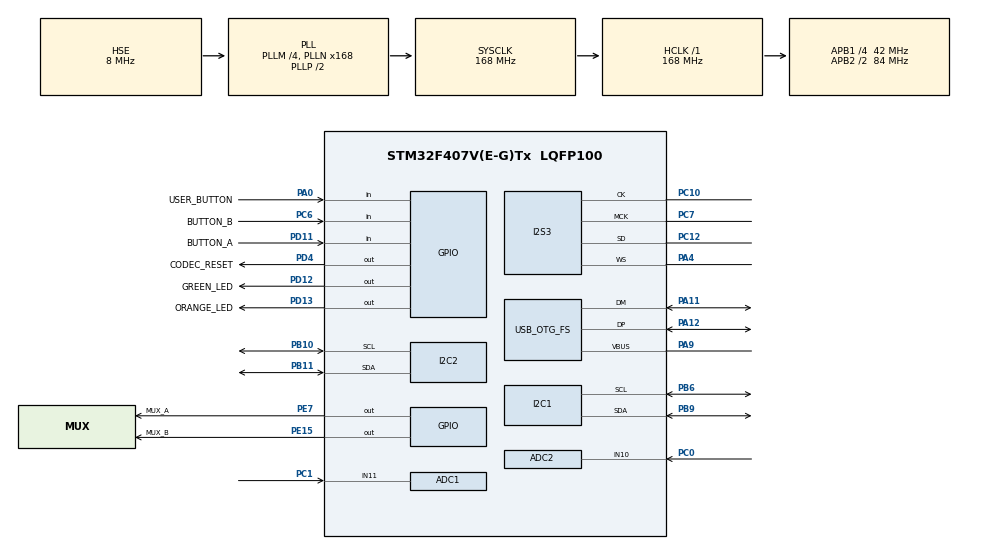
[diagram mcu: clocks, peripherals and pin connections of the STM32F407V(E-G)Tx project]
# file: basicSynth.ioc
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ADC1.Channel-1\#ChannelRegularConversion=ADC_CHANNEL_11
ADC1.ClockPrescaler=ADC_CLOCK_SYNC_PCLK_DIV8
ADC1.NbrOfConversionFlag=1
ADC1.Rank-1\#ChannelRegularConversion=1
ADC1.SamplingTime-1\#ChannelRegularConversion=ADC_SAMPLETIME_144CYCLES
ADC1.master=1
ADC2.Channel-0\#ChannelRegularConversion=ADC_CHANNEL_10
ADC2.ClockPrescaler=ADC_CLOCK_SYNC_PCLK_DIV8
ADC2.NbrOfConversionFlag=1
ADC2.Rank-0\#ChannelRegularConversion=1
ADC2.SamplingTime-0\#ChannelRegularConversion=ADC_SAMPLETIME_144CYCLES
Dma.I2C2_TX.1.Direction=DMA_MEMORY_TO_PERIPH
Dma.I2C2_TX.1.FIFOMode=DMA_FIFOMODE_DISABLE
Dma.I2C2_TX.1.Instance=DMA1_Stream7
Dma.I2C2_TX.1.MemDataAlignment=DMA_MDATAALIGN_BYTE
Dma.I2C2_TX.1.MemInc=DMA_MINC_ENABLE
Dma.I2C2_TX.1.Mode=DMA_NORMAL
Dma.I2C2_TX.1.PeriphDataAlignment=DMA_PDATAALIGN_BYTE
Dma.I2C2_TX.1.PeriphInc=DMA_PINC_DISABLE
Dma.I2C2_TX.1.Priority=DMA_PRIORITY_LOW
Dma.Request0=SPI3_TX
Dma.Request1=I2C2_TX
Dma.SPI3_TX.0.Direction=DMA_MEMORY_TO_PERIPH
Dma.SPI3_TX.0.FIFOMode=DMA_FIFOMODE_DISABLE
Dma.SPI3_TX.0.Instance=DMA1_Stream5
Dma.SPI3_TX.0.MemDataAlignment=DMA_MDATAALIGN_HALFWORD
Dma.SPI3_TX.0.MemInc=DMA_MINC_ENABLE
Dma.SPI3_TX.0.Mode=DMA_CIRCULAR
Dma.SPI3_TX.0.PeriphDataAlignment=DMA_PDATAALIGN_HALFWORD
Dma.SPI3_TX.0.PeriphInc=DMA_PINC_DISABLE
Dma.SPI3_TX.0.Priority=DMA_PRIORITY_VERY_HIGH
I2C2.I2C_Mode=I2C_Fast
I2S3.AudioFreq=I2S_AUDIOFREQ_48K
I2S3.ErrorAudioFreq=0.09 %
I2S3.FullDuplexMode=I2S_FULLDUPLEXMODE_DISABLE
I2S3.Instance=SPI$Index
I2S3.RealAudioFreq=48.046 KHz
I2S3.VirtualMode=I2S_MODE_MASTER
Mcu.Family=STM32F4
Mcu.Name=STM32F407V(E-G)Tx
Mcu.Package=LQFP100
NVIC.ADC_IRQn=true\:0\:0\:false\:false\:true\:true\:true\:true
NVIC.DMA1_Stream5_IRQn=true\:0\:0\:false\:false\:true\:false\:true\:true
NVIC.DMA1_Stream7_IRQn=true\:0\:0\:false\:false\:true\:false\:true\:true
NVIC.I2C2_ER_IRQn=true\:0\:0\:false\:false\:true\:true\:true\:true
NVIC.I2C2_EV_IRQn=true\:0\:0\:false\:false\:true\:true\:true\:true
NVIC.OTG_FS_IRQn=true\:0\:0\:false\:false\:true\:false\:true\:true
NVIC.PriorityGroup=NVIC_PRIORITYGROUP_4
NVIC.TIM4_IRQn=true\:0\:0\:false\:false\:true\:true\:true\:true
PA0-WKUP.GPIO_Label=USER_BUTTON
PA0-WKUP.GPIO_PuPd=GPIO_PULLDOWN
PA0-WKUP.Signal=GPIO_Input
PA11.Mode=Device_Only
PA11.Signal=USB_OTG_FS_DM
PA12.Mode=Device_Only
PA12.Signal=USB_OTG_FS_DP
PA4.Mode=Half_Duplex_Master
PA4.Signal=I2S3_WS
PA9.Mode=Activate_VBUS
PA9.Signal=USB_OTG_FS_VBUS
PB10.Mode=I2C
PB10.Signal=I2C2_SCL
PB11.Mode=I2C
PB11.Signal=I2C2_SDA
PB6.Mode=I2C
PB6.Signal=I2C1_SCL
PB9.Mode=I2C
PB9.Signal=I2C1_SDA
PC0.Signal=ADCx_IN10
PC1.Signal=ADCx_IN11
PC10.Mode=Half_Duplex_Master
PC10.Signal=I2S3_CK
PC12.Mode=Half_Duplex_Master
PC12.Signal=I2S3_SD
PC6.GPIO_Label=BUTTON_B
PC6.GPIO_PuPd=GPIO_PULLUP
PC6.Signal=GPIO_Input
PC7.Mode=Master_Clock_Activated
PC7.Signal=I2S3_MCK
PD11.GPIO_Label=BUTTON_A
PD11.GPIO_PuPd=GPIO_PULLUP
PD11.Signal=GPIO_Input
PD12.GPIO_Label=GREEN_LED
PD12.Signal=GPIO_Output
PD13.GPIO_Label=ORANGE_LED
PD13.Signal=GPIO_Output
PD4.GPIO_Label=CODEC_RESET
PD4.Signal=GPIO_Output
PE15.GPIO_Label=MUX_B
PE15.Signal=GPIO_Output
PE7.GPIO_Label=MUX_A
PE7.Signal=GPIO_Output
PH0-OSC_IN.Mode=HSE-External-Oscillator
PH0-OSC_IN.Signal=RCC_OSC_IN
PH1-OSC_OUT.Mode=HSE-External-Oscillator
PH1-OSC_OUT.Signal=RCC_OSC_OUT
ProjectManager.HeapSize=0xC000
ProjectManager.StackSize=0x2000
ProjectManager.TargetToolchain=CMake
RCC.48MHZClocksFreq_Value=48000000
RCC.AHBFreq_Value=168000000
RCC.APB1CLKDivider=RCC_HCLK_DIV4
RCC.APB1Freq_Value=42000000
RCC.APB1TimFreq_Value=84000000
RCC.APB2CLKDivider=RCC_HCLK_DIV2
RCC.APB2Freq_Value=84000000
RCC.APB2TimFreq_Value=168000000
RCC.CortexFreq_Value=168000000
RCC.HCLKFreq_Value=168000000
RCC.HSE_VALUE=8000000
RCC.HSI_VALUE=16000000
RCC.LSE_VALUE=32768
RCC.PLLI2SN=123
RCC.PLLM=4
RCC.PLLN=168
RCC.PLLQ=7
RCC.SYSCLKFreq_VALUE=168000000
RCC.SYSCLKSource=RCC_SYSCLKSOURCE_PLLCLK
RCC.VCOOutputFreq_Value=336000000
SH.ADCx_IN10.0=ADC2_IN10,IN10
SH.ADCx_IN11.0=ADC1_IN11,IN11
TIM4.Period=999
TIM4.Prescaler=83
USB_DEVICE.CLASS_NAME_FS=AUDIO
USB_DEVICE.VirtualMode-AUDIO_FS=Audio
USB_DEVICE.VirtualModeFS=Audio_FS
USB_OTG_FS.VirtualMode=Device_Only
VP_TIM4_VS_ClockSourceINT.Mode=Internal
VP_USB_DEVICE_VS_USB_DEVICE_AUDIO_FS.Mode=AUDIO_FS
board=custom

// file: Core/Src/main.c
/* USER CODE BEGIN Header */
/**
  ******************************************************************************
  * @file           : main.c
  * @brief          : Main program body
  ******************************************************************************
  * @attention
  *
  * Copyright (c) 2026 STMicroelectronics.
  * All rights reserved.
  *
  * This software is licensed under terms that can be found in the LICENSE file
  * in the root directory of this software component.
  * If no LICENSE file comes with this software, it is provided AS-IS.
  *
  ******************************************************************************
  */
/* USER CODE END Header */
#include "main.h"
#include "adc.h"
#include "dma.h"
#include "i2c.h"
#include "i2s.h"
#include "tim.h"
#include "usb_device.h"
#include "gpio.h"

/* USER CODE BEGIN Includes */
#include "app.h"
/* USER CODE END Includes */

void SystemClock_Config(void);

int main(void)
{

  /* MCU Configuration--------------------------------------------------------*/

  /* Reset of all peripherals, Initializes the Flash interface and the Systick. */
  HAL_Init();

  /* Configure the system clock */
  SystemClock_Config();

  /* Initialize all configured peripherals */
  MX_GPIO_Init();
  MX_DMA_Init();
  MX_I2C1_Init();
  MX_I2S3_Init();
  MX_ADC1_Init();
  MX_ADC2_Init();
  MX_TIM4_Init();
  MX_USB_DEVICE_Init();
  MX_I2C2_Init();
  /* USER CODE BEGIN 2 */
  cpp_main();
  /* USER CODE END 2 */

  /* Infinite loop */
  /* USER CODE BEGIN WHILE */
//  while (1)
//  {
    /* USER CODE END WHILE */

    /* USER CODE BEGIN 3 */
//  }
  /* USER CODE END 3 */
}

void SystemClock_Config(void)
{
  RCC_OscInitTypeDef RCC_OscInitStruct = {0};
  RCC_ClkInitTypeDef RCC_ClkInitStruct = {0};

  /** Configure the main internal regulator output voltage
  */
  __HAL_RCC_PWR_CLK_ENABLE();
  __HAL_PWR_VOLTAGESCALING_CONFIG(PWR_REGULATOR_VOLTAGE_SCALE1);

  /** Initializes the RCC Oscillators according to the specified parameters
  * in the RCC_OscInitTypeDef structure.
  */
  RCC_OscInitStruct.OscillatorType = RCC_OSCILLATORTYPE_HSE;
  RCC_OscInitStruct.HSEState = RCC_HSE_ON;
  RCC_OscInitStruct.PLL.PLLState = RCC_PLL_ON;
  RCC_OscInitStruct.PLL.PLLSource = RCC_PLLSOURCE_HSE;
  RCC_OscInitStruct.PLL.PLLM = 4;
  RCC_OscInitStruct.PLL.PLLN = 168;
  RCC_OscInitStruct.PLL.PLLP = RCC_PLLP_DIV2;
  RCC_OscInitStruct.PLL.PLLQ = 7;
  if (HAL_RCC_OscConfig(&RCC_OscInitStruct) != HAL_OK)
  {
    Error_Handler();
  }

  /** Initializes the CPU, AHB and APB buses clocks
  */
  RCC_ClkInitStruct.ClockType = RCC_CLOCKTYPE_HCLK|RCC_CLOCKTYPE_SYSCLK
                              |RCC_CLOCKTYPE_PCLK1|RCC_CLOCKTYPE_PCLK2;
  RCC_ClkInitStruct.SYSCLKSource = RCC_SYSCLKSOURCE_PLLCLK;
  RCC_ClkInitStruct.AHBCLKDivider = RCC_SYSCLK_DIV1;
  RCC_ClkInitStruct.APB1CLKDivider = RCC_HCLK_DIV4;
  RCC_ClkInitStruct.APB2CLKDivider = RCC_HCLK_DIV2;

  if (HAL_RCC_ClockConfig(&RCC_ClkInitStruct, FLASH_LATENCY_5) != HAL_OK)
  {
    Error_Handler();
  }
}

void Error_Handler(void)
{
  __disable_irq();
  while (1)
  {
  }
}
